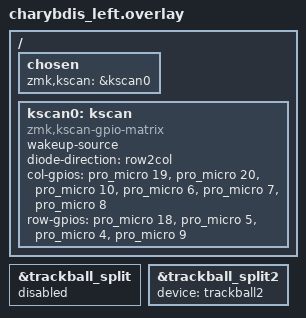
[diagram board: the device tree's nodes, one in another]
#include "charybdis.dtsi"
#include "charybdis_pmw3610.dtsi"
#include "split_input.dtsi"

/ {
    chosen {
        zmk,kscan = &kscan0;
    };

	kscan0: kscan {
        compatible = "zmk,kscan-gpio-matrix";
        wakeup-source;
        diode-direction = "row2col";
        
        col-gpios
            = <&pro_micro 19 (GPIO_ACTIVE_HIGH | GPIO_PULL_DOWN)>
            , <&pro_micro 20 (GPIO_ACTIVE_HIGH | GPIO_PULL_DOWN)>
            , <&pro_micro 10 (GPIO_ACTIVE_HIGH | GPIO_PULL_DOWN)>
            , <&pro_micro 6 (GPIO_ACTIVE_HIGH | GPIO_PULL_DOWN)>
            , <&pro_micro 7 (GPIO_ACTIVE_HIGH | GPIO_PULL_DOWN)>
            , <&pro_micro 8 (GPIO_ACTIVE_HIGH | GPIO_PULL_DOWN)>
            ;

        row-gpios
            = <&pro_micro 18 GPIO_ACTIVE_HIGH>
            , <&pro_micro 5 GPIO_ACTIVE_HIGH>
            , <&pro_micro 4 GPIO_ACTIVE_HIGH>
            , <&pro_micro 9 GPIO_ACTIVE_HIGH>
            ;
    };
};

&trackball_split {
	status = "disabled";
};

&trackball_split2 {
	device = <&trackball2>;
};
